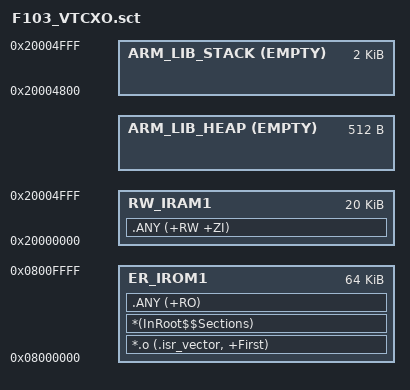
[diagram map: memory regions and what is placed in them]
; Generated by Dockyard32.
; Source linker script: cmake/generated/F103_VTCXO.ld
LR_IROM1 0x08000000 0x00010000 {
  ER_IROM1 0x08000000 0x00010000 {
    *.o (.isr_vector, +First)
    *(InRoot$$Sections)
    .ANY (+RO)
  }
  RW_IRAM1 0x20000000 0x00005000 {
    .ANY (+RW +ZI)
  }
  ARM_LIB_HEAP  +0 EMPTY 0x00000200 { }
  ARM_LIB_STACK 0x20005000 EMPTY -0x00000800 { }
}
